AUTOSAR XML (schema 4-2-2)
package /Components
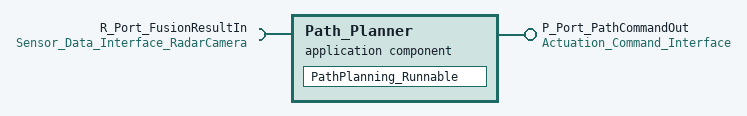
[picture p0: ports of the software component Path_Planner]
  application sw component type Path_Planner
    provide port P_Port_PathCommandOut: provided-interface=Actuation_Command_Interface
    require port R_Port_FusionResultIn: required-interface=Sensor_Data_Interface_RadarCamera
    behavior Path_Planner_BHV
      data received event PathPlanningTriggered: start-on-event=PathPlanning_Runnable
      runnable PathPlanning_Runnable: symbol=PathPlanning_Symbol
        data-receive-point-by-arguments:
          access FusionResultInput: accessed-variable={autosar-variable-in-impl-datatype={port-prototype=R_Port_FusionResultIn, target-data-prototype=RadarData}, autosar-variable=R_Port_FusionResultIn.RadarData}
        data-send-points:
          access PathCommandOutput: accessed-variable={autosar-variable-in-impl-datatype={port-prototype=P_Port_PathCommandOut, target-data-prototype=ActuationCommand}, autosar-variable=P_Port_PathCommandOut.RadarData}
